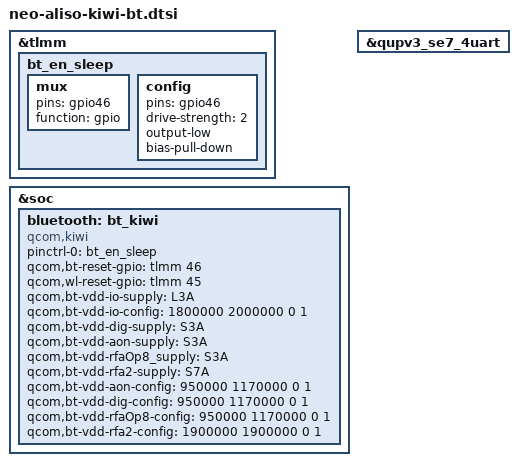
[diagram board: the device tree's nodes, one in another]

&tlmm {
	bt_en_sleep: bt_en_sleep {
		mux {
			pins = "gpio46";
			function = "gpio";
		};

		config {
			pins = "gpio46";
			drive-strength = <2>;
			output-low;
			bias-pull-down;
		};
	};
};

&soc {
	bluetooth: bt_kiwi {
		compatible = "qcom,kiwi";
		pinctrl-names = "default";
		pinctrl-0 = <&bt_en_sleep>;
		qcom,bt-reset-gpio = <&tlmm 46 0>; /* BT_EN */
		qcom,wl-reset-gpio = <&tlmm 45 0>; /* WL_EN */

		qcom,bt-vdd-io-supply = <&L3A>;  /* IO */
		/* max voltage are set to regulator max voltage supported */
		qcom,bt-vdd-io-config = <1800000 2000000 0 1>;

		qcom,bt-vdd-dig-supply    = <&S3A>; /* BT LDO*/
		qcom,bt-vdd-aon-supply    = <&S3A>; /* BT AON LDO*/
		qcom,bt-vdd-rfaOp8_supply = <&S3A>; /* BT RFAOp8 CMN LDO*/
		qcom,bt-vdd-rfa2-supply   = <&S7A>; /* BT RFA1.8 LDO */

		qcom,bt-vdd-aon-config    = <950000 1170000 0 1>;
		qcom,bt-vdd-dig-config    = <950000 1170000 0 1>;
		qcom,bt-vdd-rfaOp8-config = <950000 1170000 0 1>;
		qcom,bt-vdd-rfa2-config   = <1900000 1900000 0 1>;
	};

};

//uart instance
&qupv3_se7_4uart {
	status = "ok";
};
